# CM41x_M4 register map
Vendor: Analog Devices; Series: CM41x_M4; File version: 1p0
CPU: CM4 r0p1, little endian, MPU, FPU, 4 interrupt priority bits
Registers are 32-bit, read-write, reset 0x0 unless marked. A register's access mark holds for its fields unless they carry their own. Offsets are from the block's base; [hi:lo] are bit positions; {n}, {i} and the like mark numbered series.

## PADS1 — Pads Controller
Base 0x40001000
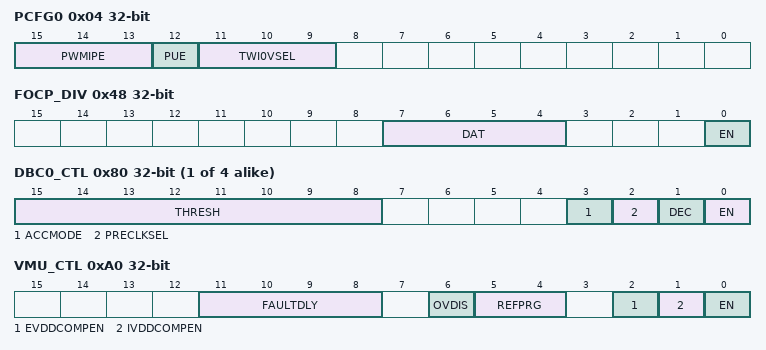
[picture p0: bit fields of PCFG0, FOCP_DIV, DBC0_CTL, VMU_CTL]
0x04 PCFG0 — Peripheral Configuration0 Register
  [15:13] PWMIPE — Input Buffer/Pull-Up Enable
  [12] PUE range 0x00000000..0x00000001 — Pull-Up Enable
  [11:9] TWI0VSEL — Drive/tolerate for TWI0 Pins SCL & SDA
0x48 FOCP_DIV — Fast Over Current Protection Clock Divisor Register
  [7:4] DAT range 0x00000000..0x0000000F — Divisor for FOCP_CLK output
  [0] EN range 0x00000000..0x00000001 — Enable
0x70 DBC_PRESCALE — Debounce Prescale Register
  [15:0] DATA range 0x00000000..0x0000FFFF — Debounce Clock Prescale Divisor
{0x80+4i} DBC{i}_CTL (i=0..3) — Debounce Control Register(s)
  [15:8] THRESH range 0x00000000..0x000000FF — Debounce Counter or Accumulator Threshold
  [3] ACCMODE — Accumulator Mode
  [2] PRECLKSEL — Prescale Clock Select
  [1] DEC — Decimating Sample Mode Enable
  [0] EN — Debounce Filter Enable (Input is bypassed directly to output if disabled)
0xA0 VMU_CTL — Voltage Monitor Unit Control Register
  [11:8] FAULTDLY range 0x00000000..0x0000000F — Fault Delay Count in AUX_CLK ticks
  [6] OVDIS range 0x00000000..0x00000001 — Comparator Over-voltage Disable
  [5:4] REFPRG range 0x00000000..0x00000003 — Comparator Reference Select
  [2] EVDDCOMPEN range 0x00000000..0x00000001 — 3Volt Over/Under Voltage Compare Enable
  [1] IVDDCOMPEN range 0x00000000..0x00000001 — 1 Volt Over/Under Voltage Compare Enable
  [0] EN range 0x00000000..0x00000001 — VMU Block Enable
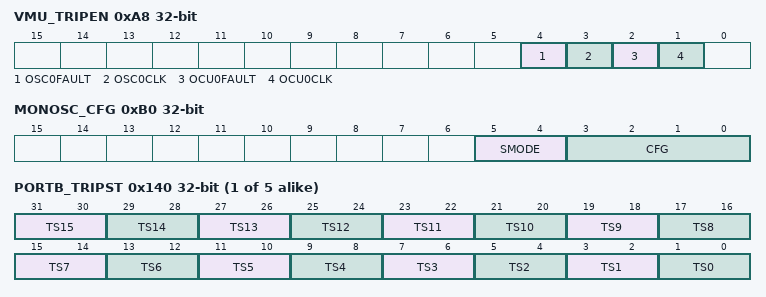
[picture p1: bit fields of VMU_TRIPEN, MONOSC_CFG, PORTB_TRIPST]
0xA8 VMU_TRIPEN — Voltage Monitor Unit Trip Enable Register
  [4] OSC0FAULT range 0x00000000..0x00000001 — System Oscillator Asynchronous Fault Trip Enable
  [3] OSC0CLK range 0x00000000..0x00000001 — System Oscillator Clock No Good Trip Enable
  [2] OCU0FAULT range 0x00000000..0x00000001 — Oscillator Compare Unit Asynchronous Fault Trip Enable
  [1] OCU0CLK range 0x00000000..0x00000001 — Oscillator Compare Unit Dead Clock Trip Enable
0xAC NVWR_RSTCTL — Non-Volatile Write Reset Control Register
  [0] EN range 0x00000000..0x00000001 — Enable for Non Volatile Write Logic
0xB0 MONOSC_CFG — Monitor Oscillator Control Register
  [5:4] SMODE range 0x00000000..0x00000003 — Sleep Mode Configuration Data
  [3:0] CFG range 0x00000000..0x0000000F — Monitor Oscillator Configuration Data
0xBC VMU_TRIM — Voltage Monitor Unit Trim Register
  [15:0] TRIM range 0x00000000..0x0000FFFF — Voltage Monitor Unit Trim value
0x100 PORT{x}_DS (x=B,C,D,E,F; step 0x4) — Multi Port Drive Strength Control Register
  [15:0] GPIO_DS range 0x00000000..0x0000FFFF — Port Drive Strength
0x120 PORT{x}_RCTL (x=B,C,D,E,F; step 0x4) — Multi Port Pull-up/Pull-down Resistor Control Register
  [15:0] REN_CTL range 0x00000000..0x0000FFFF — Port Resistor Enable Control
0x140 PORT{x}_TRIPST (x=B,C,D,E,F; step 0x4) — Multi Port Trip State Register
  [2n+1:2n] TS{n} range 0x00000000..0x00000003 (n=1..15) — Port IO {n} Trip State
  [1:0] TS0 range 0x00000000..0x00000003 — Port IO_0 Trip State
0x160 PORT{x}_TRIPSEL (x=B,C,D,E,F; step 0x4) — Multi Port Trip Select Register
  [15:0] SEL range 0x00000000..0x0000FFFF — Trip A/B Mux Select

## EMUID0 — CHIP ID For ARM Emulators
Base 0x40002000
0x20 ADIID 16-bit reset 0x4144 — Analog Devices Identification
  [15:0] VALUE ro
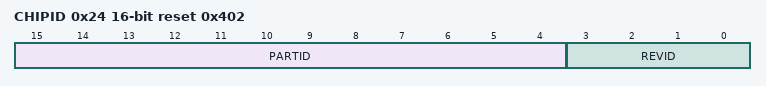
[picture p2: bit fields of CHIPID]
0x24 CHIPID 16-bit reset 0x402 — Chip Identification
  [15:4] PARTID ro, [3:0] REVID ro

## PINT0 — The Pin Interrupt module
Base 0x41002000
Same registers: PINT1 0x40003000, PINT2 0x40004000, PINT3 0x40005000, PINT4 0x40006000, PINT5 0x40007000
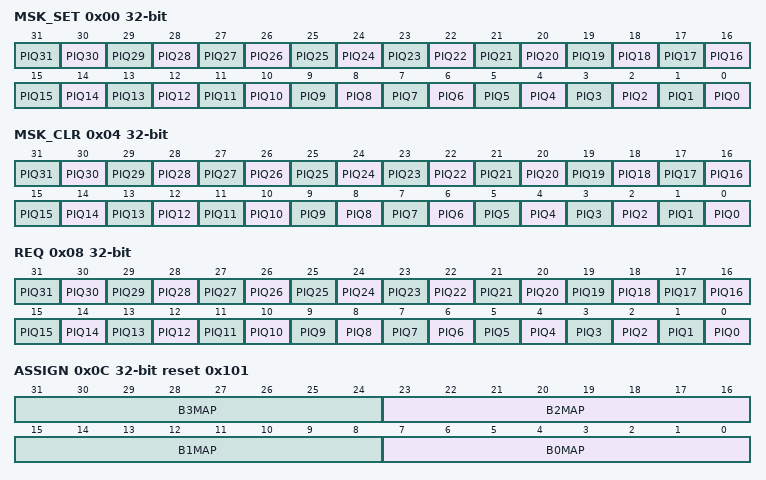
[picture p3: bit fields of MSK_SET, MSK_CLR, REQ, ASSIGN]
0x00 MSK_SET — PINT Mask Set Register
  [n] PIQ{n} range 0x00000000..0x00000001 (n=0..31) — Pin Interrupt {n} Unmask
0x04 MSK_CLR — PINT Mask Clear Register
  [n] PIQ{n} range 0x00000000..0x00000001 (n=0..31) — Pin Interrupt {n} Mask
0x08 REQ — PINT Request Register
  [n] PIQ{n} range 0x00000000..0x00000001 (n=0..31) — Pin Interrupt {n} Request
0x0C ASSIGN reset 0x101 — PINT Assign Register
  [8n+7:8n] B{n}MAP (n=0..3) — Byte {n} Mapping
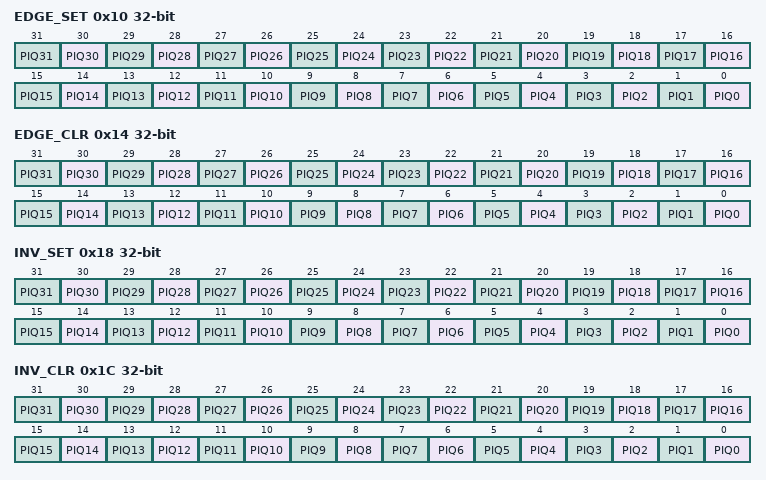
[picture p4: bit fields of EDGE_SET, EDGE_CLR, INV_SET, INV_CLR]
0x10 EDGE_SET — PINT Edge Set Register
  [n] PIQ{n} range 0x00000000..0x00000001 (n=0..31) — Pin Interrupt {n} Edge
0x14 EDGE_CLR — PINT Edge Clear Register
  [n] PIQ{n} range 0x00000000..0x00000001 (n=0..31) — Pin Interrupt {n} Level
0x18 INV_SET — PINT Invert Set Register
  [n] PIQ{n} range 0x00000000..0x00000001 (n=0..31) — Pin Interrupt {n} Invert
0x1C INV_CLR — PINT Invert Clear Register
  [n] PIQ{n} range 0x00000000..0x00000001 (n=0..31) — Pin Interrupt {n} No Invert
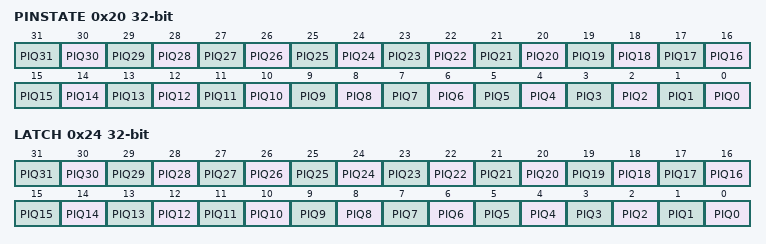
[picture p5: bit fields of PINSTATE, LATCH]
0x20 PINSTATE — PINT Pin State Register
  [n] PIQ{n} ro (n=0..31) — Pin Interrupt {n} State
0x24 LATCH — PINT Latch Register
  [n] PIQ{n} range 0x00000000..0x00000001 (n=0..31) — Pin Interrupt {n} Latch
